# VPAC0_COMMON_0_IVPAC_TOP_0_CFG_SLV_HTS_S_VBUSP register map
Vendor: Texas Instruments
Registers are 32-bit, read-write, reset 0x0 unless marked. A register's access mark holds for its fields unless they carry their own. Offsets are as the file gives them; [hi:lo] are bit positions; {n}, {i} and the like mark numbered series; 'fields as' and 'values as' point back to an identical list.

## VPAC0_COMMON_0_IVPAC_TOP_0_CFG_SLV_HTS_S_VBUSP (part 4 of 4)
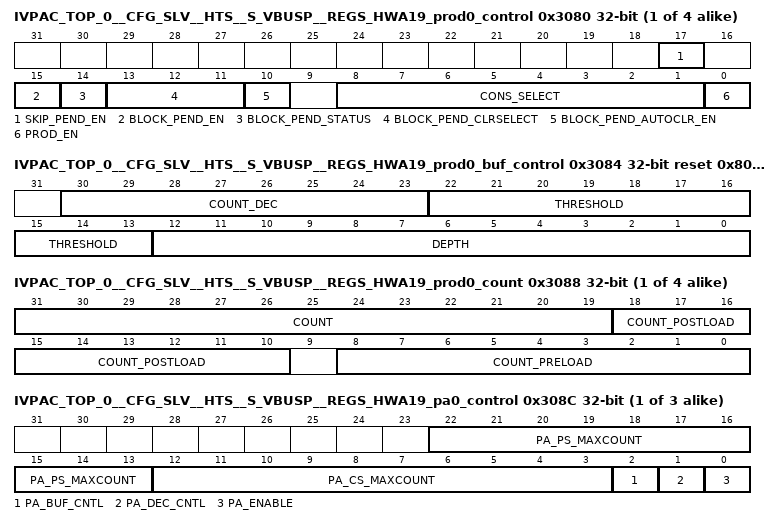
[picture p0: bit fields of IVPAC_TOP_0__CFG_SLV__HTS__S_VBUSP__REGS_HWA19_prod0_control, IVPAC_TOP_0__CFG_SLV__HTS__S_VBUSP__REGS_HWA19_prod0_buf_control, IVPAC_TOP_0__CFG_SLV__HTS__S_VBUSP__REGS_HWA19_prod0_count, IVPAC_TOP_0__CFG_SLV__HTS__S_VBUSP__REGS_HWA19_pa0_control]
{0x3080+0x20*i} IVPAC_TOP_0__CFG_SLV__HTS__S_VBUSP__REGS_HWA19_prod{i}_control (i=0..3) — Controlling producer socket{i} for HWA19
  [17] SKIP_PEND_EN — '1' -> Producer socket {i} skip enable , '0' Disable
  [15] BLOCK_PEND_EN — '1' -> block pend at the end of hwa eop enabled at Producer socket {i} , '0' Disable
  [14] BLOCK_PEND_STATUS — '1' -> block pend status at Producer socket {i} , '0' Disable
  [13:11] BLOCK_PEND_CLRSELECT — hts_event_gen[block_pend_clrselect] will be used to clear blocked pend in super pipeline
  [10] BLOCK_PEND_AUTOCLR_EN — '1' -> Enable clearing block pend status at Producer socket {i} by hts_event_gen[block_pend_clrselect], '0' Disable
  [8:1] CONS_SELECT — consumer select for HWA19 prod socket {i}. Used in decrementing count of producer buffer
  [0] PROD_EN — '1' -> Producer socket {i} enable , '0' Disable
{0x3084+0x20*i} IVPAC_TOP_0__CFG_SLV__HTS__S_VBUSP__REGS_HWA19_prod{i}_buf_control reset 0x802000 (i=0..3) — Controlling producer socket{i} buffer for HWA19
  [30:23] COUNT_DEC — Count decrement value for prod count
  [22:13] THRESHOLD — Count threshold to generate pend for consumer
  [12:0] DEPTH — Maximum number of producer buffer count
{0x3088+0x20*i} IVPAC_TOP_0__CFG_SLV__HTS__S_VBUSP__REGS_HWA19_prod{i}_count access per field (i=0..3) — Defining count values for pre/post load for generating pend by HWA19 prod{i}
  [31:19] COUNT ro — current count value
  [18:10] COUNT_POSTLOAD rw — count postload after producer max thread count reached
  [8:0] COUNT_PRELOAD rw — count preload after scheduler start/init
{0x308C+0x20*i} IVPAC_TOP_0__CFG_SLV__HTS__S_VBUSP__REGS_HWA19_pa{i}_control (i=0..2) — control register to manage pattern adapter on HWA19 prod socket{i}
  [22:13] PA_PS_MAXCOUNT — destination count for pattern adaptation (N), M --> N
  [12:3] PA_CS_MAXCOUNT — source count for pattern adaptation (M), M --> N
  [2] PA_BUF_CNTL — '1' -> Apply threshold, count_preload and count_postload on pattern adapter count (use this only when pa_enable='1') '0' -> Apply threshold, count_preload and count_postload on prod count (same behavior as if no pattern adapter. Note when pa_enable='1' and pa_buf_cntl='0' threshold is not used and ignored)
  [1] PA_DEC_CNTL — '1' -> post pattern adaptation, decrement ps count by count_dec , '0' -> post pattern adaptation, decrement ps count by pa_cs_maxcount
  [0] PA_ENABLE — '1' -> pa enable, '0' -> disable
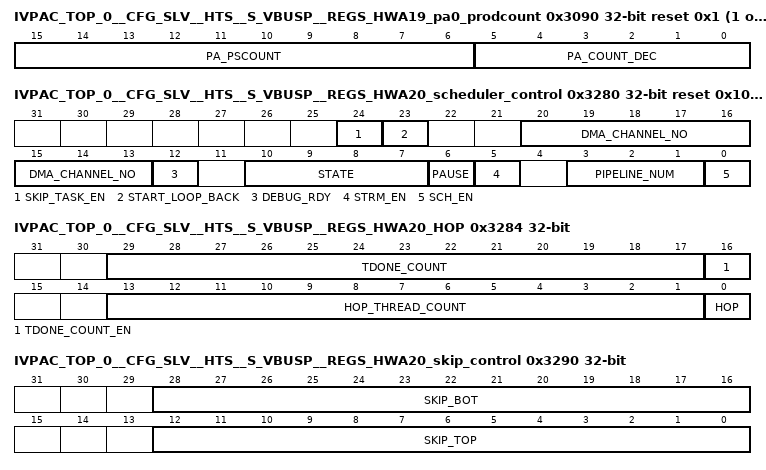
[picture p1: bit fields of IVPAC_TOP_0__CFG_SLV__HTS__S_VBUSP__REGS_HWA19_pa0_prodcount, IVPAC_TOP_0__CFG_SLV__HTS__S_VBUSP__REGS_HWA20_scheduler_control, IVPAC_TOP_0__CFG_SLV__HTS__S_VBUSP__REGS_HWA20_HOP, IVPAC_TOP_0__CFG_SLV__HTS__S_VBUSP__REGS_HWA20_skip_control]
{0x3090+0x20*i} IVPAC_TOP_0__CFG_SLV__HTS__S_VBUSP__REGS_HWA19_pa{i}_prodcount access per field reset 0x1 (i=0..2) — count values for HWA19 prod socket{i}
  [15:6] PA_PSCOUNT ro — current count value of pa prod count
  [5:0] PA_COUNT_DEC rw — Decrement count value of pa_prod_count after pattern adapter prod count reaches threshold
0x3280 IVPAC_TOP_0__CFG_SLV__HTS__S_VBUSP__REGS_HWA20_scheduler_control access per field reset 0x1000 — Scheduler Control Register
  [24] SKIP_TASK_EN rw — '1' -> task skip enable , '0' Disable
  [23] START_LOOP_BACK rw — '1' -> loop back start onto done in same cycle w/o asserting external channel start, '0' No loop back
  [20:13] DMA_CHANNEL_NO rw — DMA channel number for thread scheduler for HWA20
  [12] DEBUG_RDY rw — '0' -> HWA20 Scheduler resources must not be read during halted state. '1'-> HWA20 Scheduler resources are readable during halted state
  [10:7] STATE ro — Current state of HWA20 Scheduler
  [6] PAUSE rw — '1' -> pause/suspend scheduler , '0' -> resume scheduler
  [5] STRM_EN rw — '1' -> Streaming input enable, '0' No streaming input
  [3:1] PIPELINE_NUM rw — Pipeline Number of HWA20 Scheduler
  [0] SCH_EN rw — scheduler enable; write '1' to enable scheduler
0x3284 IVPAC_TOP_0__CFG_SLV__HTS__S_VBUSP__REGS_HWA20_HOP access per field — Scheduler HOP Control Register. Help in detecting eop within scheduler. Once configured, it counts task/channel starts and stops issuing further starts. Specifically useful for Head of pipe dma scheduler .
  [29:17] TDONE_COUNT ro — current tdone count value
  [16] TDONE_COUNT_EN rw — '1' -> Count tdone(Not impacted due to individual channel mask). Current tdone count available as read value , '0' -> No count
  [13:1] HOP_THREAD_COUNT rw — Number of Task count for Head of pipe
  [0] HOP rw — '1' -> Head of Pipe producer Sch , '0' -> No hop
0x3290 IVPAC_TOP_0__CFG_SLV__HTS__S_VBUSP__REGS_HWA20_skip_control — Scheduler Skip Control Register. If enabled in specific prod socket, tdones within skip_top and skip_bot is included in pend generation. tdone_count_en bit in HOP needs to be set to use SKIP feature.
  [28:16] SKIP_BOT — skip/ignore tdone from tdone_count=skip_bot till eop in HWA20 scheduler skip-enabled prod socket
  [12:0] SKIP_TOP — skip/ignore tdone from tdone_count=0 till tdone_count=skip_top value in HWA20 scheduler skip-enabled prod socket
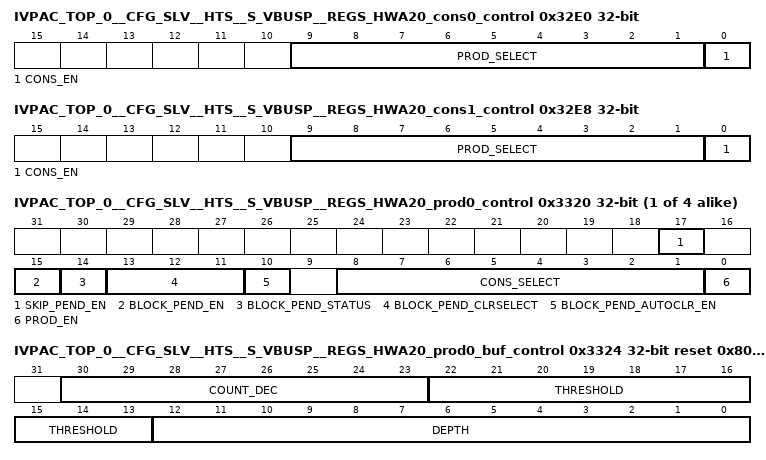
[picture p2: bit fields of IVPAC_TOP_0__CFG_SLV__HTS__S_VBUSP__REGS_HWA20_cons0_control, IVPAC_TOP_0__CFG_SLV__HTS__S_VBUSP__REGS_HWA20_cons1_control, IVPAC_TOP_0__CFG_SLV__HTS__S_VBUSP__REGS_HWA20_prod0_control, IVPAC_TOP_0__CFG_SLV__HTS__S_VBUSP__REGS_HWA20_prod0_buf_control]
0x32E0 IVPAC_TOP_0__CFG_SLV__HTS__S_VBUSP__REGS_HWA20_cons0_control — Controlling consumer socket 0 for HWA20
  [9:1] PROD_SELECT — producer select for HWA20 cons socket 0
  [0] CONS_EN — '1' -> Consumer socket 0 enable , '0' Disable
0x32E8 IVPAC_TOP_0__CFG_SLV__HTS__S_VBUSP__REGS_HWA20_cons1_control — Controlling consumer socket 1 for HWA20
  [9:1] PROD_SELECT — producer select for HWA20 cons socket 1
  [0] CONS_EN — '1' -> Consumer socket 1 enable , '0' Disable
{0x3320+0x20*i} IVPAC_TOP_0__CFG_SLV__HTS__S_VBUSP__REGS_HWA20_prod{i}_control (i=0..3) — Controlling producer socket{i} for HWA20
  [17] SKIP_PEND_EN — '1' -> Producer socket {i} skip enable , '0' Disable
  [15] BLOCK_PEND_EN — '1' -> block pend at the end of hwa eop enabled at Producer socket {i} , '0' Disable
  [14] BLOCK_PEND_STATUS — '1' -> block pend status at Producer socket {i} , '0' Disable
  [13:11] BLOCK_PEND_CLRSELECT — hts_event_gen[block_pend_clrselect] will be used to clear blocked pend in super pipeline
  [10] BLOCK_PEND_AUTOCLR_EN — '1' -> Enable clearing block pend status at Producer socket {i} by hts_event_gen[block_pend_clrselect], '0' Disable
  [8:1] CONS_SELECT — consumer select for HWA20 prod socket {i}. Used in decrementing count of producer buffer
  [0] PROD_EN — '1' -> Producer socket {i} enable , '0' Disable
{0x3324+0x20*i} IVPAC_TOP_0__CFG_SLV__HTS__S_VBUSP__REGS_HWA20_prod{i}_buf_control reset 0x802000 (i=0..3) — Controlling producer socket{i} buffer for HWA20
  fields as IVPAC_TOP_0__CFG_SLV__HTS__S_VBUSP__REGS_HWA19_prod0_buf_control
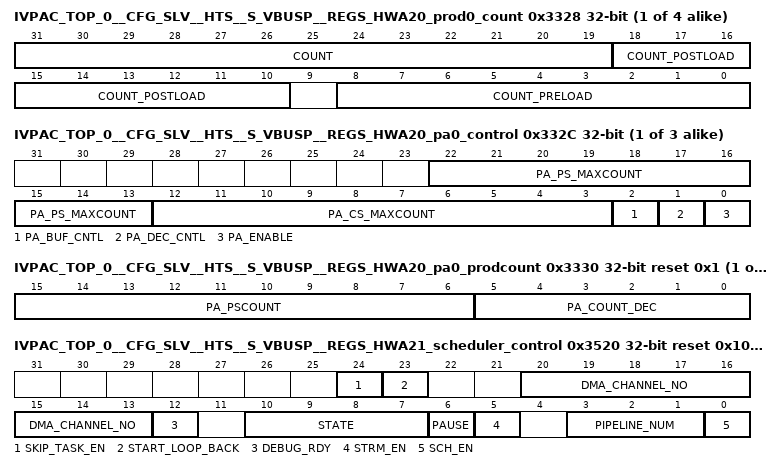
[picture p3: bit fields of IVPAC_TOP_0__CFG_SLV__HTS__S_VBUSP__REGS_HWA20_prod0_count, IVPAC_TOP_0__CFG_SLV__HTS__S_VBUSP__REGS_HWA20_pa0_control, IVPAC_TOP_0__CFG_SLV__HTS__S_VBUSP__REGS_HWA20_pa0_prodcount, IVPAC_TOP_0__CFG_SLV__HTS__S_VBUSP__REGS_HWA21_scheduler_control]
{0x3328+0x20*i} IVPAC_TOP_0__CFG_SLV__HTS__S_VBUSP__REGS_HWA20_prod{i}_count access per field (i=0..3) — Defining count values for pre/post load for generating pend by HWA20 prod{i}
  fields as IVPAC_TOP_0__CFG_SLV__HTS__S_VBUSP__REGS_HWA19_prod0_count
{0x332C+0x20*i} IVPAC_TOP_0__CFG_SLV__HTS__S_VBUSP__REGS_HWA20_pa{i}_control (i=0..2) — control register to manage pattern adapter on HWA20 prod socket{i}
  fields as IVPAC_TOP_0__CFG_SLV__HTS__S_VBUSP__REGS_HWA19_pa0_control
{0x3330+0x20*i} IVPAC_TOP_0__CFG_SLV__HTS__S_VBUSP__REGS_HWA20_pa{i}_prodcount access per field reset 0x1 (i=0..2) — count values for HWA20 prod socket{i}
  fields as IVPAC_TOP_0__CFG_SLV__HTS__S_VBUSP__REGS_HWA19_pa0_prodcount
0x3520 IVPAC_TOP_0__CFG_SLV__HTS__S_VBUSP__REGS_HWA21_scheduler_control access per field reset 0x1000 — Scheduler Control Register
  [24] SKIP_TASK_EN rw — '1' -> task skip enable , '0' Disable
  [23] START_LOOP_BACK rw — '1' -> loop back start onto done in same cycle w/o asserting external channel start, '0' No loop back
  [20:13] DMA_CHANNEL_NO rw — DMA channel number for thread scheduler for HWA21
  [12] DEBUG_RDY rw — '0' -> HWA21 Scheduler resources must not be read during halted state. '1'-> HWA21 Scheduler resources are readable during halted state
  [10:7] STATE ro — Current state of HWA21 Scheduler
  [6] PAUSE rw — '1' -> pause/suspend scheduler , '0' -> resume scheduler
  [5] STRM_EN rw — '1' -> Streaming input enable, '0' No streaming input
  [3:1] PIPELINE_NUM rw — Pipeline Number of HWA21 Scheduler
  [0] SCH_EN rw — scheduler enable; write '1' to enable scheduler
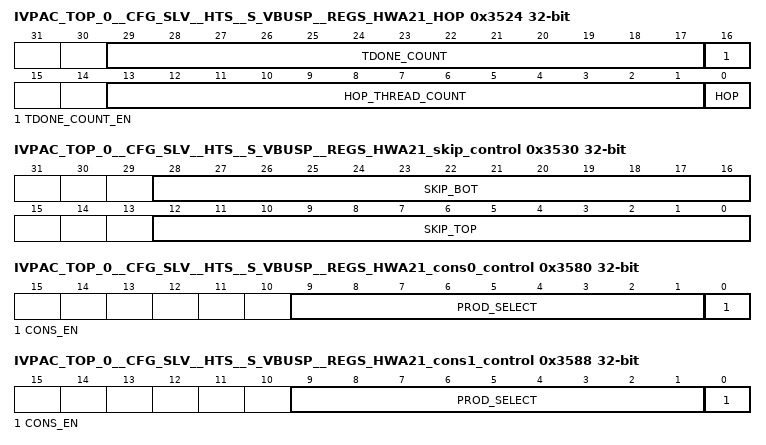
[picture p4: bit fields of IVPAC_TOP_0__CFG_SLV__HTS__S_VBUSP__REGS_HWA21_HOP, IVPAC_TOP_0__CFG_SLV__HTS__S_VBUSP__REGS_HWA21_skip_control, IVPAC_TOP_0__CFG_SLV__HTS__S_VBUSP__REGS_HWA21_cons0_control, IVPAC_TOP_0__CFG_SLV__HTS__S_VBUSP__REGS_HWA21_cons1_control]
0x3524 IVPAC_TOP_0__CFG_SLV__HTS__S_VBUSP__REGS_HWA21_HOP access per field — Scheduler HOP Control Register. Help in detecting eop within scheduler. Once configured, it counts task/channel starts and stops issuing further starts. Specifically useful for Head of pipe dma scheduler .
  fields as IVPAC_TOP_0__CFG_SLV__HTS__S_VBUSP__REGS_HWA20_HOP
0x3530 IVPAC_TOP_0__CFG_SLV__HTS__S_VBUSP__REGS_HWA21_skip_control — Scheduler Skip Control Register. If enabled in specific prod socket, tdones within skip_top and skip_bot is included in pend generation. tdone_count_en bit in HOP needs to be set to use SKIP feature.
  [28:16] SKIP_BOT — skip/ignore tdone from tdone_count=skip_bot till eop in HWA21 scheduler skip-enabled prod socket
  [12:0] SKIP_TOP — skip/ignore tdone from tdone_count=0 till tdone_count=skip_top value in HWA21 scheduler skip-enabled prod socket
0x3580 IVPAC_TOP_0__CFG_SLV__HTS__S_VBUSP__REGS_HWA21_cons0_control — Controlling consumer socket 0 for HWA21
  [9:1] PROD_SELECT — producer select for HWA21 cons socket 0
  [0] CONS_EN — '1' -> Consumer socket 0 enable , '0' Disable
0x3588 IVPAC_TOP_0__CFG_SLV__HTS__S_VBUSP__REGS_HWA21_cons1_control — Controlling consumer socket 1 for HWA21
  [9:1] PROD_SELECT — producer select for HWA21 cons socket 1
  [0] CONS_EN — '1' -> Consumer socket 1 enable , '0' Disable
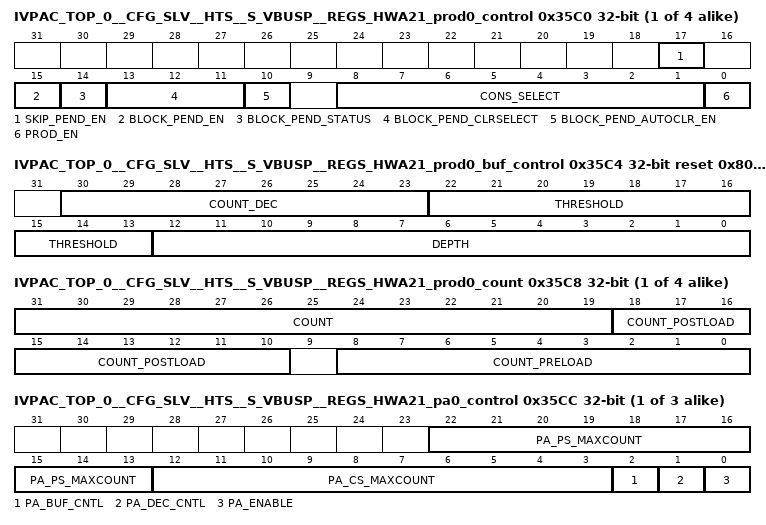
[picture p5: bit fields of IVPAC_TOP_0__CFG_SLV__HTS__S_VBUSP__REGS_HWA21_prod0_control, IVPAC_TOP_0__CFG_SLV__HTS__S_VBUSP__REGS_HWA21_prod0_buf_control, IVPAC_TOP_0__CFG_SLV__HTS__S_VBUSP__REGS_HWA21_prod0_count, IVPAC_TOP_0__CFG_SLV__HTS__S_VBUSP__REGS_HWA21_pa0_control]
{0x35C0+0x20*i} IVPAC_TOP_0__CFG_SLV__HTS__S_VBUSP__REGS_HWA21_prod{i}_control (i=0..3) — Controlling producer socket{i} for HWA21
  [17] SKIP_PEND_EN — '1' -> Producer socket {i} skip enable , '0' Disable
  [15] BLOCK_PEND_EN — '1' -> block pend at the end of hwa eop enabled at Producer socket {i} , '0' Disable
  [14] BLOCK_PEND_STATUS — '1' -> block pend status at Producer socket {i} , '0' Disable
  [13:11] BLOCK_PEND_CLRSELECT — hts_event_gen[block_pend_clrselect] will be used to clear blocked pend in super pipeline
  [10] BLOCK_PEND_AUTOCLR_EN — '1' -> Enable clearing block pend status at Producer socket {i} by hts_event_gen[block_pend_clrselect], '0' Disable
  [8:1] CONS_SELECT — consumer select for HWA21 prod socket {i}. Used in decrementing count of producer buffer
  [0] PROD_EN — '1' -> Producer socket {i} enable , '0' Disable
{0x35C4+0x20*i} IVPAC_TOP_0__CFG_SLV__HTS__S_VBUSP__REGS_HWA21_prod{i}_buf_control reset 0x802000 (i=0..3) — Controlling producer socket{i} buffer for HWA21
  fields as IVPAC_TOP_0__CFG_SLV__HTS__S_VBUSP__REGS_HWA19_prod0_buf_control
{0x35C8+0x20*i} IVPAC_TOP_0__CFG_SLV__HTS__S_VBUSP__REGS_HWA21_prod{i}_count access per field (i=0..3) — Defining count values for pre/post load for generating pend by HWA21 prod{i}
  fields as IVPAC_TOP_0__CFG_SLV__HTS__S_VBUSP__REGS_HWA19_prod0_count
{0x35CC+0x20*i} IVPAC_TOP_0__CFG_SLV__HTS__S_VBUSP__REGS_HWA21_pa{i}_control (i=0..2) — control register to manage pattern adapter on HWA21 prod socket{i}
  fields as IVPAC_TOP_0__CFG_SLV__HTS__S_VBUSP__REGS_HWA19_pa0_control
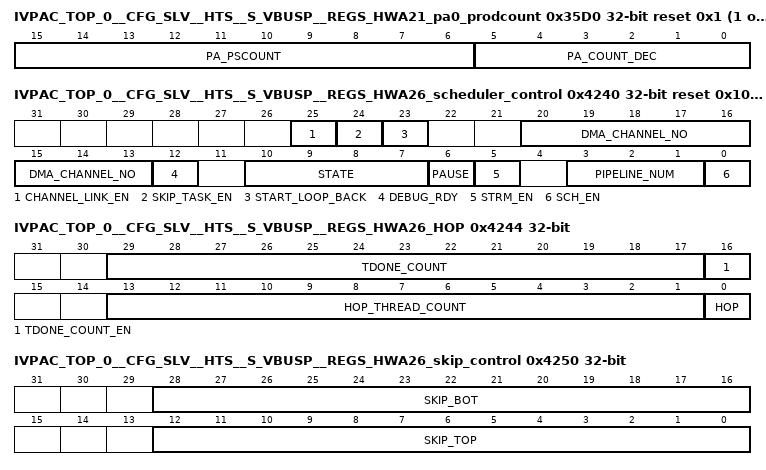
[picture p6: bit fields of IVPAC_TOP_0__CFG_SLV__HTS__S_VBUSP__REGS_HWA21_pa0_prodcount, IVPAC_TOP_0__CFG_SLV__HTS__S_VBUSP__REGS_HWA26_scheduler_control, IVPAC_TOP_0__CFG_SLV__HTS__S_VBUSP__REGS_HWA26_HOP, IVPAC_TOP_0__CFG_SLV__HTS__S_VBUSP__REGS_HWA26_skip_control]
{0x35D0+0x20*i} IVPAC_TOP_0__CFG_SLV__HTS__S_VBUSP__REGS_HWA21_pa{i}_prodcount access per field reset 0x1 (i=0..2) — count values for HWA21 prod socket{i}
  fields as IVPAC_TOP_0__CFG_SLV__HTS__S_VBUSP__REGS_HWA19_pa0_prodcount
0x4240 IVPAC_TOP_0__CFG_SLV__HTS__S_VBUSP__REGS_HWA26_scheduler_control access per field reset 0x1000 — Scheduler Control Register
  [25] CHANNEL_LINK_EN rw — '1' -> Trigger dma_channel_no for chanel_count_set0.count0 times --> Trigger dma_channel_no+1 for chanel_count_set0.count1 times --> Trigger dma_channel_no+2 for chanel_count_set1.count0 times .. repeat till either total count reaches HOP or dma_channel_no+11 wraps to dma_channel_no and process repeats till reaches HOP, '0' Disable
  [24] SKIP_TASK_EN rw — '1' -> task skip enable , '0' Disable
  [23] START_LOOP_BACK rw — '1' -> loop back start onto done in same cycle w/o asserting external channel start, '0' No loop back
  [20:13] DMA_CHANNEL_NO rw — DMA channel number for thread scheduler for HWA26
  [12] DEBUG_RDY rw — '0' -> HWA26 Scheduler resources must not be read during halted state. '1'-> HWA26 Scheduler resources are readable during halted state
  [10:7] STATE ro — Current state of HWA26 Scheduler
  [6] PAUSE rw — '1' -> pause/suspend scheduler , '0' -> resume scheduler
  [5] STRM_EN rw — '1' -> Streaming input enable, '0' No streaming input
  [3:1] PIPELINE_NUM rw — Pipeline Number of HWA26 Scheduler
  [0] SCH_EN rw — scheduler enable; write '1' to enable scheduler
0x4244 IVPAC_TOP_0__CFG_SLV__HTS__S_VBUSP__REGS_HWA26_HOP access per field — Scheduler HOP Control Register. Help in detecting eop within scheduler. Once configured, it counts task/channel starts and stops issuing further starts. Specifically useful for Head of pipe dma scheduler .
  fields as IVPAC_TOP_0__CFG_SLV__HTS__S_VBUSP__REGS_HWA20_HOP
0x4250 IVPAC_TOP_0__CFG_SLV__HTS__S_VBUSP__REGS_HWA26_skip_control — Scheduler Skip Control Register. If enabled in specific prod socket, tdones within skip_top and skip_bot is included in pend generation. tdone_count_en bit in HOP needs to be set to use SKIP feature.
  [28:16] SKIP_BOT — skip/ignore tdone from tdone_count=skip_bot till eop in HWA26 scheduler skip-enabled prod socket
  [12:0] SKIP_TOP — skip/ignore tdone from tdone_count=0 till tdone_count=skip_top value in HWA26 scheduler skip-enabled prod socket
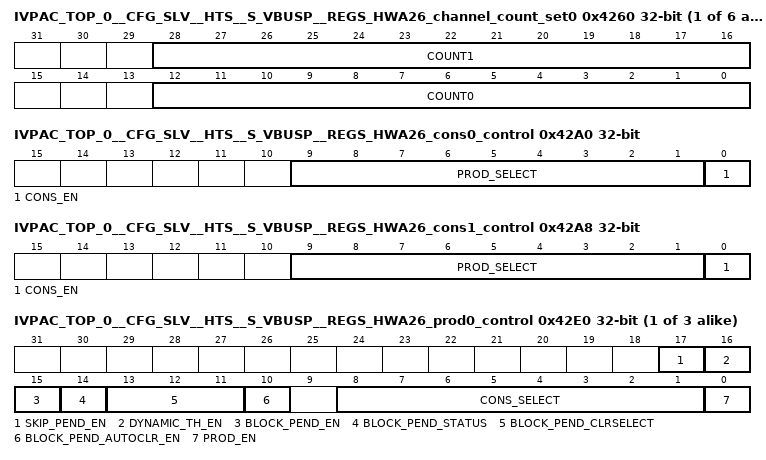
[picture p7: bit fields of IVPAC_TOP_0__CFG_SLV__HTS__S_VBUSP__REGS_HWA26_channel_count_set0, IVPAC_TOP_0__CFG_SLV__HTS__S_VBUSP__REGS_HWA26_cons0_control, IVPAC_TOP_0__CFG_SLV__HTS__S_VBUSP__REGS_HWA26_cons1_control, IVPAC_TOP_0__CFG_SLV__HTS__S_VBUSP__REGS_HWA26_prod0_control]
{0x4260+4i} IVPAC_TOP_0__CFG_SLV__HTS__S_VBUSP__REGS_HWA26_channel_count_set{i} (i=0..5) — Scheduler channel count. If enabled in specific pare scheduler configured channel number is triggered for set0.count0 followed by set0.count1 before linking to set1 parameters
  [28:16] COUNT1 — When channel_link_en is set, trigger dma_channel_no+{2i+1} HWA26_channel_count_set{i}.count1 times before linking to next HWA26_channel_count_set. set5 links to set0 if total trigger count exceeds hop_count
  [12:0] COUNT0 — When channel_link_en is set, trigger dma_channel_no+{2i} HWA26_channel_count_set{i}.count0 times before linking to count1
0x42A0 IVPAC_TOP_0__CFG_SLV__HTS__S_VBUSP__REGS_HWA26_cons0_control — Controlling consumer socket 0 for HWA26
  [9:1] PROD_SELECT — producer select for HWA26 cons socket 0
  [0] CONS_EN — '1' -> Consumer socket 0 enable , '0' Disable
0x42A8 IVPAC_TOP_0__CFG_SLV__HTS__S_VBUSP__REGS_HWA26_cons1_control — Controlling consumer socket 1 for HWA26
  [9:1] PROD_SELECT — producer select for HWA26 cons socket 1
  [0] CONS_EN — '1' -> Consumer socket 1 enable , '0' Disable
{0x42E0+0x20*i} IVPAC_TOP_0__CFG_SLV__HTS__S_VBUSP__REGS_HWA26_prod{i}_control (i=0..2) — Controlling producer socket{i} for HWA26
  [17] SKIP_PEND_EN — '1' -> Producer socket {i} skip enable , '0' Disable
  [16] DYNAMIC_TH_EN — '1' -> Dynamic Thresholding Enabled for Producer socket {i} , '0' Disable Dynamic Thresholding
  [15] BLOCK_PEND_EN — '1' -> block pend at the end of hwa eop enabled at Producer socket {i} , '0' Disable
  [14] BLOCK_PEND_STATUS — '1' -> block pend status at Producer socket {i} , '0' Disable
  [13:11] BLOCK_PEND_CLRSELECT — hts_event_gen[block_pend_clrselect] will be used to clear blocked pend in super pipeline
  [10] BLOCK_PEND_AUTOCLR_EN — '1' -> Enable clearing block pend status at Producer socket {i} by hts_event_gen[block_pend_clrselect], '0' Disable
  [8:1] CONS_SELECT — consumer select for HWA26 prod socket {i}. Used in decrementing count of producer buffer
  [0] PROD_EN — '1' -> Producer socket {i} enable , '0' Disable
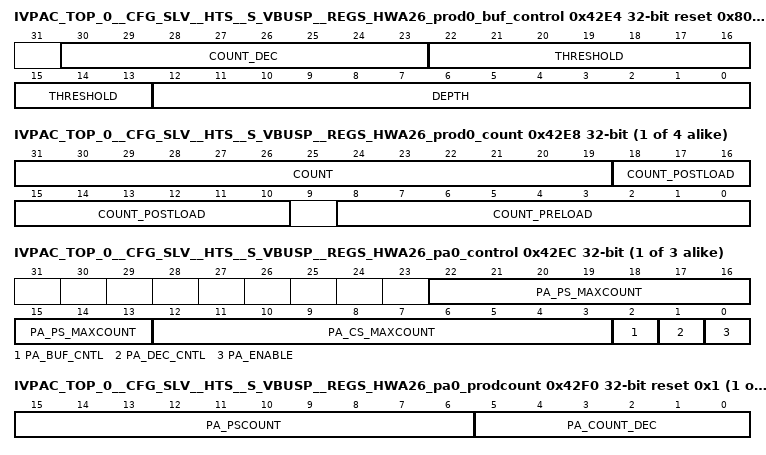
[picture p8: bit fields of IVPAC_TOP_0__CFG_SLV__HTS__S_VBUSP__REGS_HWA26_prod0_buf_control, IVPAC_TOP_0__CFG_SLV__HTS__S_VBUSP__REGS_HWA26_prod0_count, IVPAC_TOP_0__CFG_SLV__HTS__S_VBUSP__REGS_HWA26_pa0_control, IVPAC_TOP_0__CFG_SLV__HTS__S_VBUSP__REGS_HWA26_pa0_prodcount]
{0x42E4+0x20*i} IVPAC_TOP_0__CFG_SLV__HTS__S_VBUSP__REGS_HWA26_prod{i}_buf_control reset 0x802000 (i=0..3) — Controlling producer socket{i} buffer for HWA26
  fields as IVPAC_TOP_0__CFG_SLV__HTS__S_VBUSP__REGS_HWA19_prod0_buf_control
{0x42E8+0x20*i} IVPAC_TOP_0__CFG_SLV__HTS__S_VBUSP__REGS_HWA26_prod{i}_count access per field (i=0..3) — Defining count values for pre/post load for generating pend by HWA26 prod{i}
  fields as IVPAC_TOP_0__CFG_SLV__HTS__S_VBUSP__REGS_HWA19_prod0_count
{0x42EC+0x20*i} IVPAC_TOP_0__CFG_SLV__HTS__S_VBUSP__REGS_HWA26_pa{i}_control (i=0..2) — control register to manage pattern adapter on HWA26 prod socket{i}
  fields as IVPAC_TOP_0__CFG_SLV__HTS__S_VBUSP__REGS_HWA19_pa0_control
{0x42F0+0x20*i} IVPAC_TOP_0__CFG_SLV__HTS__S_VBUSP__REGS_HWA26_pa{i}_prodcount access per field reset 0x1 (i=0..2) — count values for HWA26 prod socket{i}
  fields as IVPAC_TOP_0__CFG_SLV__HTS__S_VBUSP__REGS_HWA19_pa0_prodcount
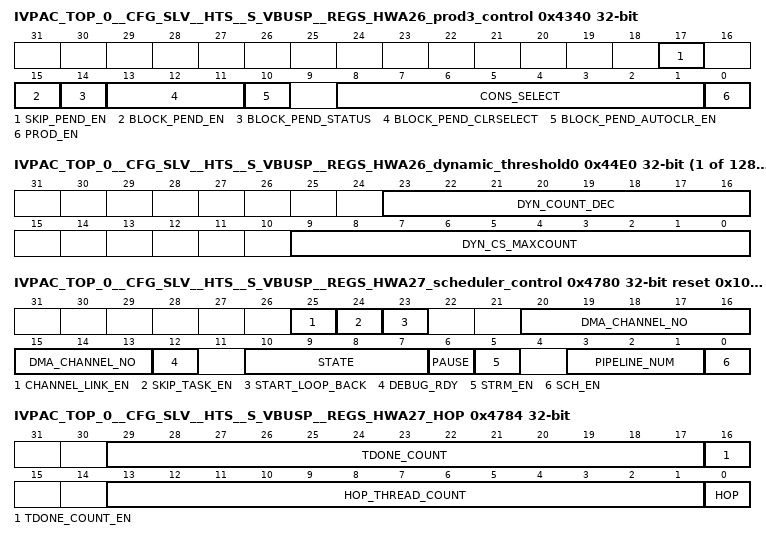
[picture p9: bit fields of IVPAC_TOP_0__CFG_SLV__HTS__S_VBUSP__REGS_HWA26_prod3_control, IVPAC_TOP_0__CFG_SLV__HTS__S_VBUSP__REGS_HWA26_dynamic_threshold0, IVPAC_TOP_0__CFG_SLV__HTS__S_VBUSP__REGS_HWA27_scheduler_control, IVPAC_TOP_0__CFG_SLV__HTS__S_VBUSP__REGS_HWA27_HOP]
0x4340 IVPAC_TOP_0__CFG_SLV__HTS__S_VBUSP__REGS_HWA26_prod3_control — Controlling producer socket3 for HWA26
  [17] SKIP_PEND_EN — '1' -> Producer socket 3 skip enable , '0' Disable
  [15] BLOCK_PEND_EN — '1' -> block pend at the end of hwa eop enabled at Producer socket 3 , '0' Disable
  [14] BLOCK_PEND_STATUS — '1' -> block pend status at Producer socket 3 , '0' Disable
  [13:11] BLOCK_PEND_CLRSELECT — hts_event_gen[block_pend_clrselect] will be used to clear blocked pend in super pipeline
  [10] BLOCK_PEND_AUTOCLR_EN — '1' -> Enable clearing block pend status at Producer socket 3 by hts_event_gen[block_pend_clrselect], '0' Disable
  [8:1] CONS_SELECT — consumer select for HWA26 prod socket 3. Used in decrementing count of producer buffer
  [0] PROD_EN — '1' -> Producer socket 3 enable , '0' Disable
{0x44E0+4i} IVPAC_TOP_0__CFG_SLV__HTS__S_VBUSP__REGS_HWA26_dynamic_threshold{i} (i=0..127) — csmaxcount and count_dec value for Row No {i}. Only used alongwith Pattern Adapter feature, i.e. PA need to be enabled for this feature
  [23:16] DYN_COUNT_DEC — Prod count dec after pattern adaptation of Row No {i} when dynamic threshold feature is enabled
  [9:0] DYN_CS_MAXCOUNT — Source count for pattern adaptation of Row No {i} when dynamic threshold feature is enabled
0x4780 IVPAC_TOP_0__CFG_SLV__HTS__S_VBUSP__REGS_HWA27_scheduler_control access per field reset 0x1000 — Scheduler Control Register
  [25] CHANNEL_LINK_EN rw — '1' -> Trigger dma_channel_no for chanel_count_set0.count0 times --> Trigger dma_channel_no+1 for chanel_count_set0.count1 times --> Trigger dma_channel_no+2 for chanel_count_set1.count0 times .. repeat till either total count reaches HOP or dma_channel_no+11 wraps to dma_channel_no and process repeats till reaches HOP, '0' Disable
  [24] SKIP_TASK_EN rw — '1' -> task skip enable , '0' Disable
  [23] START_LOOP_BACK rw — '1' -> loop back start onto done in same cycle w/o asserting external channel start, '0' No loop back
  [20:13] DMA_CHANNEL_NO rw — DMA channel number for thread scheduler for HWA27
  [12] DEBUG_RDY rw — '0' -> HWA27 Scheduler resources must not be read during halted state. '1'-> HWA27 Scheduler resources are readable during halted state
  [10:7] STATE ro — Current state of HWA27 Scheduler
  [6] PAUSE rw — '1' -> pause/suspend scheduler , '0' -> resume scheduler
  [5] STRM_EN rw — '1' -> Streaming input enable, '0' No streaming input
  [3:1] PIPELINE_NUM rw — Pipeline Number of HWA27 Scheduler
  [0] SCH_EN rw — scheduler enable; write '1' to enable scheduler
0x4784 IVPAC_TOP_0__CFG_SLV__HTS__S_VBUSP__REGS_HWA27_HOP access per field — Scheduler HOP Control Register. Help in detecting eop within scheduler. Once configured, it counts task/channel starts and stops issuing further starts. Specifically useful for Head of pipe dma scheduler .
  fields as IVPAC_TOP_0__CFG_SLV__HTS__S_VBUSP__REGS_HWA20_HOP
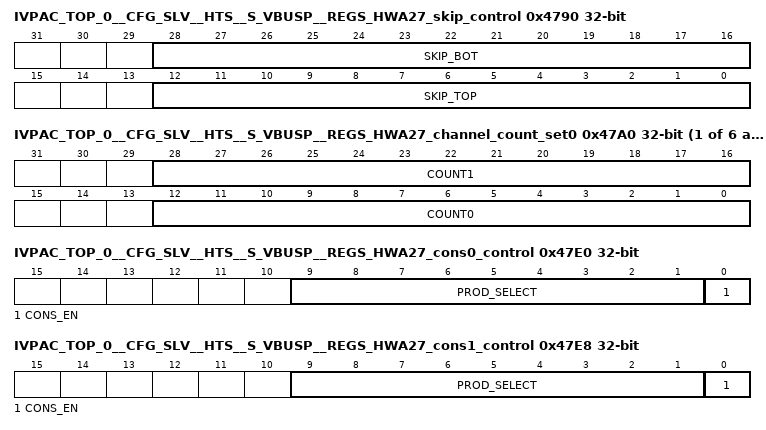
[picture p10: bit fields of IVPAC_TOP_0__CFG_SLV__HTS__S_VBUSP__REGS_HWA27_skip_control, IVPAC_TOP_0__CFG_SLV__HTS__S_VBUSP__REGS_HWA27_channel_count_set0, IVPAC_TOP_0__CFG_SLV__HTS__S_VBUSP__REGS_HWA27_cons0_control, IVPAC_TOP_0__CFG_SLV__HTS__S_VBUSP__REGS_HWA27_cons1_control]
0x4790 IVPAC_TOP_0__CFG_SLV__HTS__S_VBUSP__REGS_HWA27_skip_control — Scheduler Skip Control Register. If enabled in specific prod socket, tdones within skip_top and skip_bot is included in pend generation. tdone_count_en bit in HOP needs to be set to use SKIP feature.
  [28:16] SKIP_BOT — skip/ignore tdone from tdone_count=skip_bot till eop in HWA27 scheduler skip-enabled prod socket
  [12:0] SKIP_TOP — skip/ignore tdone from tdone_count=0 till tdone_count=skip_top value in HWA27 scheduler skip-enabled prod socket
{0x47A0+4i} IVPAC_TOP_0__CFG_SLV__HTS__S_VBUSP__REGS_HWA27_channel_count_set{i} (i=0..5) — Scheduler channel count. If enabled in specific pare scheduler configured channel number is triggered for set0.count0 followed by set0.count1 before linking to set1 parameters
  [28:16] COUNT1 — When channel_link_en is set, trigger dma_channel_no+{2i+1} HWA27_channel_count_set{i}.count1 times before linking to next HWA27_channel_count_set. set5 links to set0 if total trigger count exceeds hop_count
  [12:0] COUNT0 — When channel_link_en is set, trigger dma_channel_no+{2i} HWA27_channel_count_set{i}.count0 times before linking to count1
0x47E0 IVPAC_TOP_0__CFG_SLV__HTS__S_VBUSP__REGS_HWA27_cons0_control — Controlling consumer socket 0 for HWA27
  [9:1] PROD_SELECT — producer select for HWA27 cons socket 0
  [0] CONS_EN — '1' -> Consumer socket 0 enable , '0' Disable
0x47E8 IVPAC_TOP_0__CFG_SLV__HTS__S_VBUSP__REGS_HWA27_cons1_control — Controlling consumer socket 1 for HWA27
  [9:1] PROD_SELECT — producer select for HWA27 cons socket 1
  [0] CONS_EN — '1' -> Consumer socket 1 enable , '0' Disable
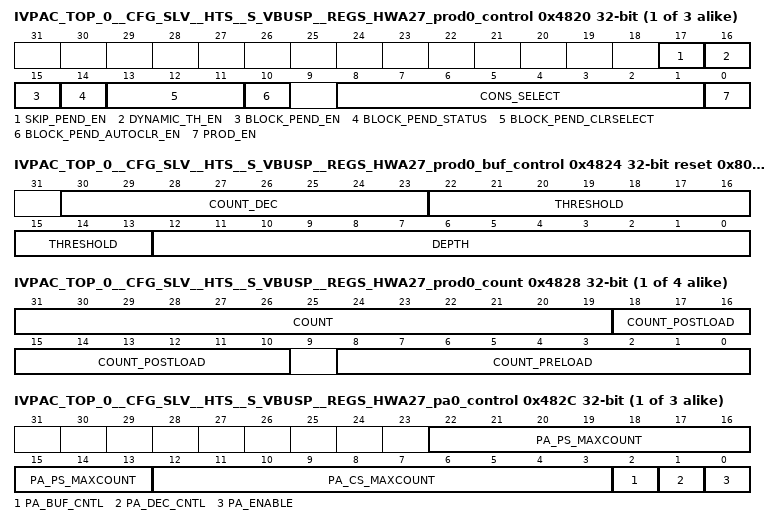
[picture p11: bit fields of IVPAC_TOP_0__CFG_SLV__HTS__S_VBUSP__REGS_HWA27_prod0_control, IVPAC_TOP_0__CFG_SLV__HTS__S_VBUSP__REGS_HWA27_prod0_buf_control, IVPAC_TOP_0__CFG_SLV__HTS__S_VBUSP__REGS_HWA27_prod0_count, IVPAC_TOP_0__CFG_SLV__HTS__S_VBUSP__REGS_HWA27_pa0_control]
{0x4820+0x20*i} IVPAC_TOP_0__CFG_SLV__HTS__S_VBUSP__REGS_HWA27_prod{i}_control (i=0..2) — Controlling producer socket{i} for HWA27
  [17] SKIP_PEND_EN — '1' -> Producer socket {i} skip enable , '0' Disable
  [16] DYNAMIC_TH_EN — '1' -> Dynamic Thresholding Enabled for Producer socket {i} , '0' Disable Dynamic Thresholding
  [15] BLOCK_PEND_EN — '1' -> block pend at the end of hwa eop enabled at Producer socket {i} , '0' Disable
  [14] BLOCK_PEND_STATUS — '1' -> block pend status at Producer socket {i} , '0' Disable
  [13:11] BLOCK_PEND_CLRSELECT — hts_event_gen[block_pend_clrselect] will be used to clear blocked pend in super pipeline
  [10] BLOCK_PEND_AUTOCLR_EN — '1' -> Enable clearing block pend status at Producer socket {i} by hts_event_gen[block_pend_clrselect], '0' Disable
  [8:1] CONS_SELECT — consumer select for HWA27 prod socket {i}. Used in decrementing count of producer buffer
  [0] PROD_EN — '1' -> Producer socket {i} enable , '0' Disable
{0x4824+0x20*i} IVPAC_TOP_0__CFG_SLV__HTS__S_VBUSP__REGS_HWA27_prod{i}_buf_control reset 0x802000 (i=0..3) — Controlling producer socket{i} buffer for HWA27
  fields as IVPAC_TOP_0__CFG_SLV__HTS__S_VBUSP__REGS_HWA19_prod0_buf_control
{0x4828+0x20*i} IVPAC_TOP_0__CFG_SLV__HTS__S_VBUSP__REGS_HWA27_prod{i}_count access per field (i=0..3) — Defining count values for pre/post load for generating pend by HWA27 prod{i}
  fields as IVPAC_TOP_0__CFG_SLV__HTS__S_VBUSP__REGS_HWA19_prod0_count
{0x482C+0x20*i} IVPAC_TOP_0__CFG_SLV__HTS__S_VBUSP__REGS_HWA27_pa{i}_control (i=0..2) — control register to manage pattern adapter on HWA27 prod socket{i}
  fields as IVPAC_TOP_0__CFG_SLV__HTS__S_VBUSP__REGS_HWA19_pa0_control
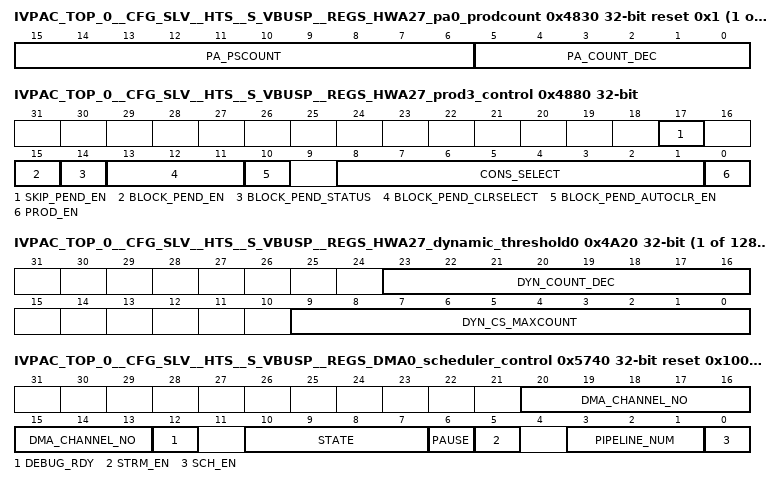
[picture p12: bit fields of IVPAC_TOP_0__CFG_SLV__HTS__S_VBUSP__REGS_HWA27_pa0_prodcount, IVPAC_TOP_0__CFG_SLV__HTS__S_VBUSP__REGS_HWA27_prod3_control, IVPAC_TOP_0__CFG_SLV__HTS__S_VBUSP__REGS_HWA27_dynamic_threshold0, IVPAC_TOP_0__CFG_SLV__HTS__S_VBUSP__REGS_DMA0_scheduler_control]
{0x4830+0x20*i} IVPAC_TOP_0__CFG_SLV__HTS__S_VBUSP__REGS_HWA27_pa{i}_prodcount access per field reset 0x1 (i=0..2) — count values for HWA27 prod socket{i}
  fields as IVPAC_TOP_0__CFG_SLV__HTS__S_VBUSP__REGS_HWA19_pa0_prodcount
0x4880 IVPAC_TOP_0__CFG_SLV__HTS__S_VBUSP__REGS_HWA27_prod3_control — Controlling producer socket3 for HWA27
  [17] SKIP_PEND_EN — '1' -> Producer socket 3 skip enable , '0' Disable
  [15] BLOCK_PEND_EN — '1' -> block pend at the end of hwa eop enabled at Producer socket 3 , '0' Disable
  [14] BLOCK_PEND_STATUS — '1' -> block pend status at Producer socket 3 , '0' Disable
  [13:11] BLOCK_PEND_CLRSELECT — hts_event_gen[block_pend_clrselect] will be used to clear blocked pend in super pipeline
  [10] BLOCK_PEND_AUTOCLR_EN — '1' -> Enable clearing block pend status at Producer socket 3 by hts_event_gen[block_pend_clrselect], '0' Disable
  [8:1] CONS_SELECT — consumer select for HWA27 prod socket 3. Used in decrementing count of producer buffer
  [0] PROD_EN — '1' -> Producer socket 3 enable , '0' Disable
{0x4A20+4i} IVPAC_TOP_0__CFG_SLV__HTS__S_VBUSP__REGS_HWA27_dynamic_threshold{i} (i=0..127) — csmaxcount and count_dec value for Row No {i}. Only used alongwith Pattern Adapter feature, i.e. PA need to be enabled for this feature
  fields as IVPAC_TOP_0__CFG_SLV__HTS__S_VBUSP__REGS_HWA26_dynamic_threshold0
{0x5740+0x40*i} IVPAC_TOP_0__CFG_SLV__HTS__S_VBUSP__REGS_DMA{i}_scheduler_control access per field reset 0x1000 (i=0..4) — Scheduler Control Register
  [20:13] DMA_CHANNEL_NO rw — DMA channel number for thread scheduler for DMA{i}
  [12] DEBUG_RDY rw — '0' -> DMA{i} Scheduler resources must not be read during halted state. '1'-> DMA{i} Scheduler resources are readable during halted state
  [10:7] STATE ro — Current state of DMA{i} Scheduler
  [6] PAUSE rw — '1' -> pause/suspend scheduler , '0' -> resume scheduler
  [5] STRM_EN rw — '1' -> Streaming input enable, '0' No streaming input
  [3:1] PIPELINE_NUM rw — Pipeline Number of DMA{i} Scheduler
  [0] SCH_EN rw — scheduler enable; write '1' to enable scheduler
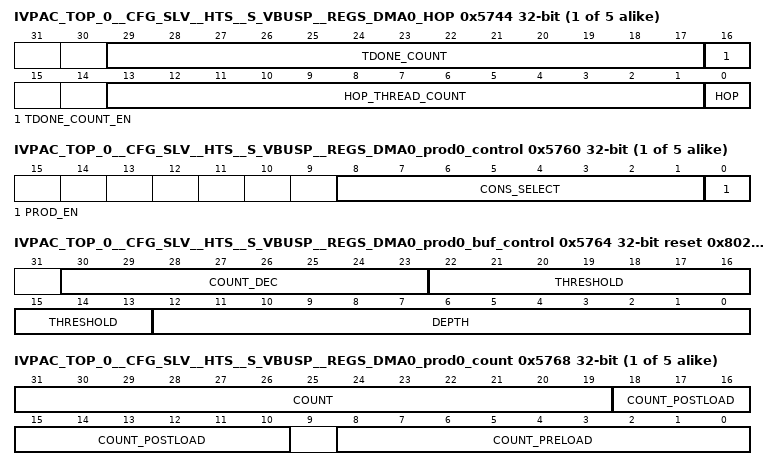
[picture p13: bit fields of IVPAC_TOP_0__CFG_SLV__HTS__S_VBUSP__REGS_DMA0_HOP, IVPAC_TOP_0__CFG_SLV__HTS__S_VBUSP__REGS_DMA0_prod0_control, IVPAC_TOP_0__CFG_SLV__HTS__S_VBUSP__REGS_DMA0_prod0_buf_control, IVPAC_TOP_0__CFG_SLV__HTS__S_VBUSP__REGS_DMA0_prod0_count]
{0x5744+0x40*i} IVPAC_TOP_0__CFG_SLV__HTS__S_VBUSP__REGS_DMA{i}_HOP access per field (i=0..4) — Scheduler HOP Control Register. Help in detecting eop within scheduler. Once configured, it counts task/channel starts and stops issuing further starts. Specifically useful for Head of pipe dma scheduler .
  fields as IVPAC_TOP_0__CFG_SLV__HTS__S_VBUSP__REGS_HWA20_HOP
{0x5760+0x40*i} IVPAC_TOP_0__CFG_SLV__HTS__S_VBUSP__REGS_DMA{i}_prod0_control (i=0..4) — Controlling producer socket0 for DMA{i}
  [8:1] CONS_SELECT — consumer select for DMA{i} prod socket 0. Used in decrementing count of producer buffer
  [0] PROD_EN — '1' -> Producer socket 0 enable , '0' Disable
{0x5764+0x40*i} IVPAC_TOP_0__CFG_SLV__HTS__S_VBUSP__REGS_DMA{i}_prod0_buf_control reset 0x802000 (i=0..4) — Controlling producer socket0 buffer for DMA{i}
  fields as IVPAC_TOP_0__CFG_SLV__HTS__S_VBUSP__REGS_HWA19_prod0_buf_control
{0x5768+0x40*i} IVPAC_TOP_0__CFG_SLV__HTS__S_VBUSP__REGS_DMA{i}_prod0_count access per field (i=0..4) — Defining count values for pre/post load for generating pend by DMA{i} prod0
  fields as IVPAC_TOP_0__CFG_SLV__HTS__S_VBUSP__REGS_HWA19_prod0_count
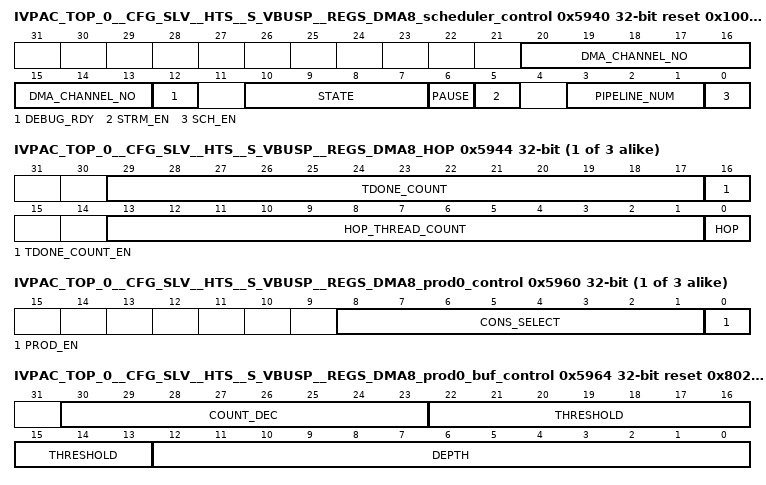
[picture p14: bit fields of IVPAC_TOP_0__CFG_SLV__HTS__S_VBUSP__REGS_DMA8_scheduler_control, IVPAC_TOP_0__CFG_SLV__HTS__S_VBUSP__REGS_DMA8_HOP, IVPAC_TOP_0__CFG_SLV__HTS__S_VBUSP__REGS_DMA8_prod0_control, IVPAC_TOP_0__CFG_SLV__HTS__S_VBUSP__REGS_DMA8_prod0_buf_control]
{0x5740+0x40*i} IVPAC_TOP_0__CFG_SLV__HTS__S_VBUSP__REGS_DMA{i}_scheduler_control access per field reset 0x1000 (i=8..10) — Scheduler Control Register
  fields as IVPAC_TOP_0__CFG_SLV__HTS__S_VBUSP__REGS_DMA0_scheduler_control
{0x5744+0x40*i} IVPAC_TOP_0__CFG_SLV__HTS__S_VBUSP__REGS_DMA{i}_HOP access per field (i=8..10) — Scheduler HOP Control Register. Help in detecting eop within scheduler. Once configured, it counts task/channel starts and stops issuing further starts. Specifically useful for Head of pipe dma scheduler .
  fields as IVPAC_TOP_0__CFG_SLV__HTS__S_VBUSP__REGS_HWA20_HOP
{0x5760+0x40*i} IVPAC_TOP_0__CFG_SLV__HTS__S_VBUSP__REGS_DMA{i}_prod0_control (i=8..10) — Controlling producer socket0 for DMA{i}
  fields as IVPAC_TOP_0__CFG_SLV__HTS__S_VBUSP__REGS_DMA0_prod0_control
{0x5764+0x40*i} IVPAC_TOP_0__CFG_SLV__HTS__S_VBUSP__REGS_DMA{i}_prod0_buf_control reset 0x802000 (i=8..10) — Controlling producer socket0 buffer for DMA{i}
  fields as IVPAC_TOP_0__CFG_SLV__HTS__S_VBUSP__REGS_HWA19_prod0_buf_control
{0x5768+0x40*i} IVPAC_TOP_0__CFG_SLV__HTS__S_VBUSP__REGS_DMA{i}_prod0_count access per field (i=8..10) — Defining count values for pre/post load for generating pend by DMA{i} prod0
  fields as IVPAC_TOP_0__CFG_SLV__HTS__S_VBUSP__REGS_HWA19_prod0_count
{0x576C+0x40*i} IVPAC_TOP_0__CFG_SLV__HTS__S_VBUSP__REGS_DMA{i}_pa0_control (i=8..10) — control register to manage pattern adapter on DMA{i} prod socket0
  fields as IVPAC_TOP_0__CFG_SLV__HTS__S_VBUSP__REGS_HWA19_pa0_control
{0x5770+0x40*i} IVPAC_TOP_0__CFG_SLV__HTS__S_VBUSP__REGS_DMA{i}_pa0_prodcount access per field reset 0x1 (i=8..10) — count values for HWA{i} prod socket0
  fields as IVPAC_TOP_0__CFG_SLV__HTS__S_VBUSP__REGS_HWA19_pa0_prodcount
0x5F40 IVPAC_TOP_0__CFG_SLV__HTS__S_VBUSP__REGS_DMA32_scheduler_control access per field reset 0x1000 — Scheduler Control Register
  [20:13] DMA_CHANNEL_NO rw — DMA channel number for thread scheduler for DMA32
  [12] DEBUG_RDY rw — '0' -> DMA32 Scheduler resources must not be read during halted state. '1'-> DMA32 Scheduler resources are readable during halted state
  [10:7] STATE ro — Current state of DMA32 Scheduler
  [6] PAUSE rw — '1' -> pause/suspend scheduler , '0' -> resume scheduler
  [5] STRM_EN rw — '1' -> Streaming input enable, '0' No streaming input
  [3:1] PIPELINE_NUM rw — Pipeline Number of DMA32 Scheduler
  [0] SCH_EN rw — scheduler enable; write '1' to enable scheduler
0x5F44 IVPAC_TOP_0__CFG_SLV__HTS__S_VBUSP__REGS_DMA32_HOP access per field — Scheduler HOP Control Register. Help in detecting eop within scheduler. Once configured, it counts task/channel starts and stops issuing further starts. Specifically useful for Head of pipe dma scheduler .
  fields as IVPAC_TOP_0__CFG_SLV__HTS__S_VBUSP__REGS_HWA20_HOP
0x5F60 IVPAC_TOP_0__CFG_SLV__HTS__S_VBUSP__REGS_DMA32_prod0_control — Controlling producer socket0 for DMA32
  [8:1] CONS_SELECT — consumer select for DMA32 prod socket 0. Used in decrementing count of producer buffer
  [0] PROD_EN — '1' -> Producer socket 0 enable , '0' Disable
0x5F64 IVPAC_TOP_0__CFG_SLV__HTS__S_VBUSP__REGS_DMA32_prod0_buf_control reset 0x802000 — Controlling producer socket0 buffer for DMA32
  fields as IVPAC_TOP_0__CFG_SLV__HTS__S_VBUSP__REGS_HWA19_prod0_buf_control
0x5F68 IVPAC_TOP_0__CFG_SLV__HTS__S_VBUSP__REGS_DMA32_prod0_count access per field — Defining count values for pre/post load for generating pend by DMA32 prod0
  fields as IVPAC_TOP_0__CFG_SLV__HTS__S_VBUSP__REGS_HWA19_prod0_count
0x5F6C IVPAC_TOP_0__CFG_SLV__HTS__S_VBUSP__REGS_DMA32_pa0_control — control register to manage pattern adapter on DMA32 prod socket0
  fields as IVPAC_TOP_0__CFG_SLV__HTS__S_VBUSP__REGS_HWA19_pa0_control
0x5F70 IVPAC_TOP_0__CFG_SLV__HTS__S_VBUSP__REGS_DMA32_pa0_prodcount access per field reset 0x1 — count values for HWA32 prod socket0
  fields as IVPAC_TOP_0__CFG_SLV__HTS__S_VBUSP__REGS_HWA19_pa0_prodcount
0x5F80 IVPAC_TOP_0__CFG_SLV__HTS__S_VBUSP__REGS_DMA33_scheduler_control access per field reset 0x1000 — Scheduler Control Register
  [20:13] DMA_CHANNEL_NO rw — DMA channel number for thread scheduler for DMA33
  [12] DEBUG_RDY rw — '0' -> DMA33 Scheduler resources must not be read during halted state. '1'-> DMA33 Scheduler resources are readable during halted state
  [10:7] STATE ro — Current state of DMA33 Scheduler
  [6] PAUSE rw — '1' -> pause/suspend scheduler , '0' -> resume scheduler
  [5] STRM_EN rw — '1' -> Streaming input enable, '0' No streaming input
  [3:1] PIPELINE_NUM rw — Pipeline Number of DMA33 Scheduler
  [0] SCH_EN rw — scheduler enable; write '1' to enable scheduler
0x5F84 IVPAC_TOP_0__CFG_SLV__HTS__S_VBUSP__REGS_DMA33_HOP access per field — Scheduler HOP Control Register. Help in detecting eop within scheduler. Once configured, it counts task/channel starts and stops issuing further starts. Specifically useful for Head of pipe dma scheduler .
  fields as IVPAC_TOP_0__CFG_SLV__HTS__S_VBUSP__REGS_HWA20_HOP
0x5FA0 IVPAC_TOP_0__CFG_SLV__HTS__S_VBUSP__REGS_DMA33_prod0_control — Controlling producer socket0 for DMA33
  [8:1] CONS_SELECT — consumer select for DMA33 prod socket 0. Used in decrementing count of producer buffer
  [0] PROD_EN — '1' -> Producer socket 0 enable , '0' Disable
0x5FA4 IVPAC_TOP_0__CFG_SLV__HTS__S_VBUSP__REGS_DMA33_prod0_buf_control reset 0x802000 — Controlling producer socket0 buffer for DMA33
  fields as IVPAC_TOP_0__CFG_SLV__HTS__S_VBUSP__REGS_HWA19_prod0_buf_control
0x5FA8 IVPAC_TOP_0__CFG_SLV__HTS__S_VBUSP__REGS_DMA33_prod0_count access per field — Defining count values for pre/post load for generating pend by DMA33 prod0
  fields as IVPAC_TOP_0__CFG_SLV__HTS__S_VBUSP__REGS_HWA19_prod0_count
0x5FAC IVPAC_TOP_0__CFG_SLV__HTS__S_VBUSP__REGS_DMA33_pa0_control — control register to manage pattern adapter on DMA33 prod socket0
  fields as IVPAC_TOP_0__CFG_SLV__HTS__S_VBUSP__REGS_HWA19_pa0_control
0x5FB0 IVPAC_TOP_0__CFG_SLV__HTS__S_VBUSP__REGS_DMA33_pa0_prodcount access per field reset 0x1 — count values for HWA33 prod socket0
  fields as IVPAC_TOP_0__CFG_SLV__HTS__S_VBUSP__REGS_HWA19_pa0_prodcount
0x6140 IVPAC_TOP_0__CFG_SLV__HTS__S_VBUSP__REGS_DMA40_scheduler_control access per field reset 0x1000 — Scheduler Control Register
  [20:13] DMA_CHANNEL_NO rw — DMA channel number for thread scheduler for DMA40
  [12] DEBUG_RDY rw — '0' -> DMA40 Scheduler resources must not be read during halted state. '1'-> DMA40 Scheduler resources are readable during halted state
  [10:7] STATE ro — Current state of DMA40 Scheduler
  [6] PAUSE rw — '1' -> pause/suspend scheduler , '0' -> resume scheduler
  [5] STRM_EN rw — '1' -> Streaming input enable, '0' No streaming input
  [3:1] PIPELINE_NUM rw — Pipeline Number of DMA40 Scheduler
  [0] SCH_EN rw — scheduler enable; write '1' to enable scheduler
0x6144 IVPAC_TOP_0__CFG_SLV__HTS__S_VBUSP__REGS_DMA40_HOP access per field — Scheduler HOP Control Register. Help in detecting eop within scheduler. Once configured, it counts task/channel starts and stops issuing further starts. Specifically useful for Head of pipe dma scheduler .
  fields as IVPAC_TOP_0__CFG_SLV__HTS__S_VBUSP__REGS_HWA20_HOP
0x6160 IVPAC_TOP_0__CFG_SLV__HTS__S_VBUSP__REGS_DMA40_prod0_control — Controlling producer socket0 for DMA40
  [8:1] CONS_SELECT — consumer select for DMA40 prod socket 0. Used in decrementing count of producer buffer
  [0] PROD_EN — '1' -> Producer socket 0 enable , '0' Disable
0x6164 IVPAC_TOP_0__CFG_SLV__HTS__S_VBUSP__REGS_DMA40_prod0_buf_control reset 0x802000 — Controlling producer socket0 buffer for DMA40
  fields as IVPAC_TOP_0__CFG_SLV__HTS__S_VBUSP__REGS_HWA19_prod0_buf_control
0x6168 IVPAC_TOP_0__CFG_SLV__HTS__S_VBUSP__REGS_DMA40_prod0_count access per field — Defining count values for pre/post load for generating pend by DMA40 prod0
  fields as IVPAC_TOP_0__CFG_SLV__HTS__S_VBUSP__REGS_HWA19_prod0_count
0x616C IVPAC_TOP_0__CFG_SLV__HTS__S_VBUSP__REGS_DMA40_pa0_control — control register to manage pattern adapter on DMA40 prod socket0
  fields as IVPAC_TOP_0__CFG_SLV__HTS__S_VBUSP__REGS_HWA19_pa0_control
0x6170 IVPAC_TOP_0__CFG_SLV__HTS__S_VBUSP__REGS_DMA40_pa0_prodcount access per field reset 0x1 — count values for HWA40 prod socket0
  fields as IVPAC_TOP_0__CFG_SLV__HTS__S_VBUSP__REGS_HWA19_pa0_prodcount
0x6180 IVPAC_TOP_0__CFG_SLV__HTS__S_VBUSP__REGS_DMA41_scheduler_control access per field reset 0x1000 — Scheduler Control Register
  [20:13] DMA_CHANNEL_NO rw — DMA channel number for thread scheduler for DMA41
  [12] DEBUG_RDY rw — '0' -> DMA41 Scheduler resources must not be read during halted state. '1'-> DMA41 Scheduler resources are readable during halted state
  [10:7] STATE ro — Current state of DMA41 Scheduler
  [6] PAUSE rw — '1' -> pause/suspend scheduler , '0' -> resume scheduler
  [5] STRM_EN rw — '1' -> Streaming input enable, '0' No streaming input
  [3:1] PIPELINE_NUM rw — Pipeline Number of DMA41 Scheduler
  [0] SCH_EN rw — scheduler enable; write '1' to enable scheduler
0x6184 IVPAC_TOP_0__CFG_SLV__HTS__S_VBUSP__REGS_DMA41_HOP access per field — Scheduler HOP Control Register. Help in detecting eop within scheduler. Once configured, it counts task/channel starts and stops issuing further starts. Specifically useful for Head of pipe dma scheduler .
  fields as IVPAC_TOP_0__CFG_SLV__HTS__S_VBUSP__REGS_HWA20_HOP
0x61A0 IVPAC_TOP_0__CFG_SLV__HTS__S_VBUSP__REGS_DMA41_prod0_control — Controlling producer socket0 for DMA41
  [8:1] CONS_SELECT — consumer select for DMA41 prod socket 0. Used in decrementing count of producer buffer
  [0] PROD_EN — '1' -> Producer socket 0 enable , '0' Disable
0x61A4 IVPAC_TOP_0__CFG_SLV__HTS__S_VBUSP__REGS_DMA41_prod0_buf_control reset 0x802000 — Controlling producer socket0 buffer for DMA41
  fields as IVPAC_TOP_0__CFG_SLV__HTS__S_VBUSP__REGS_HWA19_prod0_buf_control
0x61A8 IVPAC_TOP_0__CFG_SLV__HTS__S_VBUSP__REGS_DMA41_prod0_count access per field — Defining count values for pre/post load for generating pend by DMA41 prod0
  fields as IVPAC_TOP_0__CFG_SLV__HTS__S_VBUSP__REGS_HWA19_prod0_count
0x61AC IVPAC_TOP_0__CFG_SLV__HTS__S_VBUSP__REGS_DMA41_pa0_control — control register to manage pattern adapter on DMA41 prod socket0
  fields as IVPAC_TOP_0__CFG_SLV__HTS__S_VBUSP__REGS_HWA19_pa0_control
0x61B0 IVPAC_TOP_0__CFG_SLV__HTS__S_VBUSP__REGS_DMA41_pa0_prodcount access per field reset 0x1 — count values for HWA41 prod socket0
  fields as IVPAC_TOP_0__CFG_SLV__HTS__S_VBUSP__REGS_HWA19_pa0_prodcount
0x6340 IVPAC_TOP_0__CFG_SLV__HTS__S_VBUSP__REGS_DMA48_scheduler_control access per field reset 0x1000 — Scheduler Control Register
  [20:13] DMA_CHANNEL_NO rw — DMA channel number for thread scheduler for DMA48
  [12] DEBUG_RDY rw — '0' -> DMA48 Scheduler resources must not be read during halted state. '1'-> DMA48 Scheduler resources are readable during halted state
  [10:7] STATE ro — Current state of DMA48 Scheduler
  [6] PAUSE rw — '1' -> pause/suspend scheduler , '0' -> resume scheduler
  [5] STRM_EN rw — '1' -> Streaming input enable, '0' No streaming input
  [3:1] PIPELINE_NUM rw — Pipeline Number of DMA48 Scheduler
  [0] SCH_EN rw — scheduler enable; write '1' to enable scheduler
0x6344 IVPAC_TOP_0__CFG_SLV__HTS__S_VBUSP__REGS_DMA48_HOP access per field — Scheduler HOP Control Register. Help in detecting eop within scheduler. Once configured, it counts task/channel starts and stops issuing further starts. Specifically useful for Head of pipe dma scheduler .
  fields as IVPAC_TOP_0__CFG_SLV__HTS__S_VBUSP__REGS_HWA20_HOP
0x6360 IVPAC_TOP_0__CFG_SLV__HTS__S_VBUSP__REGS_DMA48_prod0_control — Controlling producer socket0 for DMA48
  [8:1] CONS_SELECT — consumer select for DMA48 prod socket 0. Used in decrementing count of producer buffer
  [0] PROD_EN — '1' -> Producer socket 0 enable , '0' Disable
0x6364 IVPAC_TOP_0__CFG_SLV__HTS__S_VBUSP__REGS_DMA48_prod0_buf_control reset 0x802000 — Controlling producer socket0 buffer for DMA48
  fields as IVPAC_TOP_0__CFG_SLV__HTS__S_VBUSP__REGS_HWA19_prod0_buf_control
0x6368 IVPAC_TOP_0__CFG_SLV__HTS__S_VBUSP__REGS_DMA48_prod0_count access per field — Defining count values for pre/post load for generating pend by DMA48 prod0
  fields as IVPAC_TOP_0__CFG_SLV__HTS__S_VBUSP__REGS_HWA19_prod0_count
{0x5740+0x40*i} IVPAC_TOP_0__CFG_SLV__HTS__S_VBUSP__REGS_DMA{i}_scheduler_control access per field reset 0x1000 (i=56..59) — Scheduler Control Register
  fields as IVPAC_TOP_0__CFG_SLV__HTS__S_VBUSP__REGS_DMA0_scheduler_control
{0x5744+0x40*i} IVPAC_TOP_0__CFG_SLV__HTS__S_VBUSP__REGS_DMA{i}_HOP access per field (i=56..59) — Scheduler HOP Control Register. Help in detecting eop within scheduler. Once configured, it counts task/channel starts and stops issuing further starts. Specifically useful for Head of pipe dma scheduler .
  fields as IVPAC_TOP_0__CFG_SLV__HTS__S_VBUSP__REGS_HWA20_HOP
{0x5760+0x40*i} IVPAC_TOP_0__CFG_SLV__HTS__S_VBUSP__REGS_DMA{i}_prod0_control (i=56..59) — Controlling producer socket0 for DMA{i}
  fields as IVPAC_TOP_0__CFG_SLV__HTS__S_VBUSP__REGS_DMA0_prod0_control
{0x5764+0x40*i} IVPAC_TOP_0__CFG_SLV__HTS__S_VBUSP__REGS_DMA{i}_prod0_buf_control reset 0x802000 (i=56..59) — Controlling producer socket0 buffer for DMA{i}
  fields as IVPAC_TOP_0__CFG_SLV__HTS__S_VBUSP__REGS_HWA19_prod0_buf_control
{0x5768+0x40*i} IVPAC_TOP_0__CFG_SLV__HTS__S_VBUSP__REGS_DMA{i}_prod0_count access per field (i=56..59) — Defining count values for pre/post load for generating pend by DMA{i} prod0
  fields as IVPAC_TOP_0__CFG_SLV__HTS__S_VBUSP__REGS_HWA19_prod0_count
{0x5740+0x40*i} IVPAC_TOP_0__CFG_SLV__HTS__S_VBUSP__REGS_DMA{i}_scheduler_control access per field reset 0x1000 (i=64..67) — Scheduler Control Register
  fields as IVPAC_TOP_0__CFG_SLV__HTS__S_VBUSP__REGS_DMA0_scheduler_control
{0x5744+0x40*i} IVPAC_TOP_0__CFG_SLV__HTS__S_VBUSP__REGS_DMA{i}_HOP access per field (i=64..67) — Scheduler HOP Control Register. Help in detecting eop within scheduler. Once configured, it counts task/channel starts and stops issuing further starts. Specifically useful for Head of pipe dma scheduler .
  fields as IVPAC_TOP_0__CFG_SLV__HTS__S_VBUSP__REGS_HWA20_HOP
{0x5760+0x40*i} IVPAC_TOP_0__CFG_SLV__HTS__S_VBUSP__REGS_DMA{i}_prod0_control (i=64..67) — Controlling producer socket0 for DMA{i}
  fields as IVPAC_TOP_0__CFG_SLV__HTS__S_VBUSP__REGS_DMA0_prod0_control
{0x5764+0x40*i} IVPAC_TOP_0__CFG_SLV__HTS__S_VBUSP__REGS_DMA{i}_prod0_buf_control reset 0x802000 (i=64..67) — Controlling producer socket0 buffer for DMA{i}
  fields as IVPAC_TOP_0__CFG_SLV__HTS__S_VBUSP__REGS_HWA19_prod0_buf_control
{0x5768+0x40*i} IVPAC_TOP_0__CFG_SLV__HTS__S_VBUSP__REGS_DMA{i}_prod0_count access per field (i=64..67) — Defining count values for pre/post load for generating pend by DMA{i} prod0
  fields as IVPAC_TOP_0__CFG_SLV__HTS__S_VBUSP__REGS_HWA19_prod0_count
{0x6DC0+0x28*i} IVPAC_TOP_0__CFG_SLV__HTS__S_VBUSP__REGS_DMA{i}_scheduler_control access per field reset 0x1000 (i=240..245) — Scheduler Control Register
  fields as IVPAC_TOP_0__CFG_SLV__HTS__S_VBUSP__REGS_DMA0_scheduler_control
{0x6DE0+0x28*i} IVPAC_TOP_0__CFG_SLV__HTS__S_VBUSP__REGS_DMA{i}_cons0_control (i=240..245) — Controlling consumer socket 0 for DMA{i}
  [9:1] PROD_SELECT — producer select for DMA{i} cons socket 0
  [0] CONS_EN — '1' -> Consumer socket 0 enable , '0' Disable
{0x6DC0+0x28*i} IVPAC_TOP_0__CFG_SLV__HTS__S_VBUSP__REGS_DMA{i}_scheduler_control access per field reset 0x1000 (i=256..261) — Scheduler Control Register
  fields as IVPAC_TOP_0__CFG_SLV__HTS__S_VBUSP__REGS_DMA0_scheduler_control
{0x6DE0+0x28*i} IVPAC_TOP_0__CFG_SLV__HTS__S_VBUSP__REGS_DMA{i}_cons0_control (i=256..261) — Controlling consumer socket 0 for DMA{i}
  fields as IVPAC_TOP_0__CFG_SLV__HTS__S_VBUSP__REGS_DMA240_cons0_control
{0x6DC0+0x28*i} IVPAC_TOP_0__CFG_SLV__HTS__S_VBUSP__REGS_DMA{i}_scheduler_control access per field reset 0x1000 (i=272..275) — Scheduler Control Register
  fields as IVPAC_TOP_0__CFG_SLV__HTS__S_VBUSP__REGS_DMA0_scheduler_control
{0x6DE0+0x28*i} IVPAC_TOP_0__CFG_SLV__HTS__S_VBUSP__REGS_DMA{i}_cons0_control (i=272..275) — Controlling consumer socket 0 for DMA{i}
  fields as IVPAC_TOP_0__CFG_SLV__HTS__S_VBUSP__REGS_DMA240_cons0_control
{0x6DC0+0x28*i} IVPAC_TOP_0__CFG_SLV__HTS__S_VBUSP__REGS_DMA{i}_scheduler_control access per field reset 0x1000 (i=288..291) — Scheduler Control Register
  fields as IVPAC_TOP_0__CFG_SLV__HTS__S_VBUSP__REGS_DMA0_scheduler_control
{0x6DE0+0x28*i} IVPAC_TOP_0__CFG_SLV__HTS__S_VBUSP__REGS_DMA{i}_cons0_control (i=288..291) — Controlling consumer socket 0 for DMA{i}
  fields as IVPAC_TOP_0__CFG_SLV__HTS__S_VBUSP__REGS_DMA240_cons0_control
{0x6DC0+0x28*i} IVPAC_TOP_0__CFG_SLV__HTS__S_VBUSP__REGS_DMA{i}_scheduler_control access per field reset 0x1000 (i=304..313) — Scheduler Control Register
  fields as IVPAC_TOP_0__CFG_SLV__HTS__S_VBUSP__REGS_DMA0_scheduler_control
{0x6DE0+0x28*i} IVPAC_TOP_0__CFG_SLV__HTS__S_VBUSP__REGS_DMA{i}_cons0_control (i=304..313) — Controlling consumer socket 0 for DMA{i}
  fields as IVPAC_TOP_0__CFG_SLV__HTS__S_VBUSP__REGS_DMA240_cons0_control
0xA240 IVPAC_TOP_0__CFG_SLV__HTS__S_VBUSP__REGS_DMA336_scheduler_control access per field reset 0x1000 — Scheduler Control Register
  [20:13] DMA_CHANNEL_NO rw — DMA channel number for thread scheduler for DMA336
  [12] DEBUG_RDY rw — '0' -> DMA336 Scheduler resources must not be read during halted state. '1'-> DMA336 Scheduler resources are readable during halted state
  [10:7] STATE ro — Current state of DMA336 Scheduler
  [6] PAUSE rw — '1' -> pause/suspend scheduler , '0' -> resume scheduler
  [5] STRM_EN rw — '1' -> Streaming input enable, '0' No streaming input
  [3:1] PIPELINE_NUM rw — Pipeline Number of DMA336 Scheduler
  [0] SCH_EN rw — scheduler enable; write '1' to enable scheduler
0xA260 IVPAC_TOP_0__CFG_SLV__HTS__S_VBUSP__REGS_DMA336_cons0_control — Controlling consumer socket 0 for DMA336
  [9:1] PROD_SELECT — producer select for DMA336 cons socket 0
  [0] CONS_EN — '1' -> Consumer socket 0 enable , '0' Disable
{0x6DC0+0x28*i} IVPAC_TOP_0__CFG_SLV__HTS__S_VBUSP__REGS_DMA{i}_scheduler_control access per field reset 0x1000 (i=352..355) — Scheduler Control Register
  fields as IVPAC_TOP_0__CFG_SLV__HTS__S_VBUSP__REGS_DMA0_scheduler_control
{0x6DE0+0x28*i} IVPAC_TOP_0__CFG_SLV__HTS__S_VBUSP__REGS_DMA{i}_cons0_control (i=352..355) — Controlling consumer socket 0 for DMA{i}
  fields as IVPAC_TOP_0__CFG_SLV__HTS__S_VBUSP__REGS_DMA240_cons0_control
{0x6DC0+0x28*i} IVPAC_TOP_0__CFG_SLV__HTS__S_VBUSP__REGS_DMA{i}_scheduler_control access per field reset 0x1000 (i=368..371) — Scheduler Control Register
  fields as IVPAC_TOP_0__CFG_SLV__HTS__S_VBUSP__REGS_DMA0_scheduler_control
{0x6DE0+0x28*i} IVPAC_TOP_0__CFG_SLV__HTS__S_VBUSP__REGS_DMA{i}_cons0_control (i=368..371) — Controlling consumer socket 0 for DMA{i}
  fields as IVPAC_TOP_0__CFG_SLV__HTS__S_VBUSP__REGS_DMA240_cons0_control
